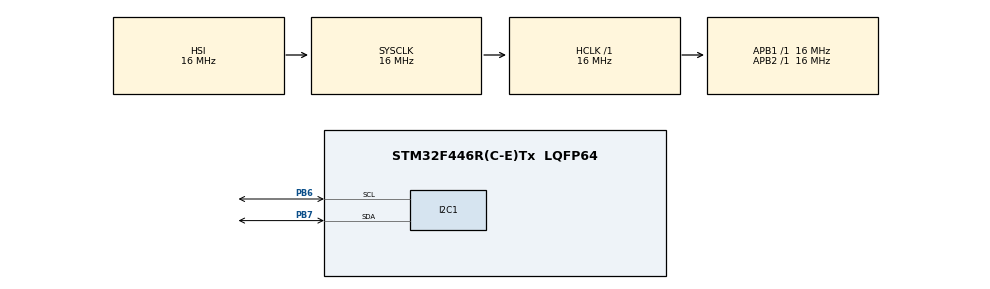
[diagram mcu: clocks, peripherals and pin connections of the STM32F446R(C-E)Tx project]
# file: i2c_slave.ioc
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I2C1.I2C_Mode=I2C_Fast
Mcu.Family=STM32F4
Mcu.Name=STM32F446R(C-E)Tx
Mcu.Package=LQFP64
NVIC.PriorityGroup=NVIC_PRIORITYGROUP_4
PB6.Mode=I2C
PB6.Signal=I2C1_SCL
PB7.Mode=I2C
PB7.Signal=I2C1_SDA
ProjectManager.HeapSize=0x200
ProjectManager.StackSize=0x400
ProjectManager.TargetToolchain=STM32CubeIDE
RCC.AHBFreq_Value=16000000
RCC.APB1Freq_Value=16000000
RCC.APB1TimFreq_Value=16000000
RCC.APB2Freq_Value=16000000
RCC.APB2TimFreq_Value=16000000
RCC.CortexFreq_Value=16000000
RCC.HCLKFreq_Value=16000000
RCC.SYSCLKFreq_VALUE=16000000
RCC.USBFreq_Value=96000000
RCC.VCOOutputFreq_Value=192000000
board=custom

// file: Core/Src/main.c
/* USER CODE BEGIN Header */
/**
  ******************************************************************************
  * @file           : main.c
  * @brief          : Main program body
  ******************************************************************************
  * @attention
  *
  * Copyright (c) 2026 STMicroelectronics.
  * All rights reserved.
  *
  * This software is licensed under terms that can be found in the LICENSE file
  * in the root directory of this software component.
  * If no LICENSE file comes with this software, it is provided AS-IS.
  *
  ******************************************************************************
  */
/* USER CODE END Header */
#include "main.h"

/* USER CODE BEGIN PD */
#define I2C_SLAVE_ADDR  0x50U   // 마스터(C2000)의 I2C_SLAVE_ADDR 과 동일 (7비트)
#define I2C_TX_BYTES    2U      // 마스터의 I2C_READ_BYTES 와 동일

/* USER CODE END PD */

I2C_HandleTypeDef hi2c1;

/* USER CODE BEGIN PV */
uint8_t txData[I2C_TX_BYTES] = {0x12, 0x34};   // 마스터로 보낼 데이터
volatile uint32_t txCount = 0;                   // 송신 성공 횟수 (디버깅용)

/* USER CODE END PV */

void SystemClock_Config(void);
static void MX_GPIO_Init(void);
static void MX_I2C1_Init(void);

int main(void)
{

  /* MCU Configuration--------------------------------------------------------*/

  /* Reset of all peripherals, Initializes the Flash interface and the Systick. */
  HAL_Init();

  /* Configure the system clock */
  SystemClock_Config();

  /* Initialize all configured peripherals */
  MX_GPIO_Init();
  MX_I2C1_Init();

  /* Infinite loop */
  while (1)
  {

    /* USER CODE BEGIN 3 */
    // 마스터가 자기 주소(0x50)로 READ 요청할 때까지 대기 후 txData 송신
    if (HAL_I2C_Slave_Transmit(&hi2c1, txData, I2C_TX_BYTES, 1000) == HAL_OK)
    {
      txCount++;
      txData[1]++;          // 테스트용: 매번 값이 바뀌는지 마스터에서 확인
    }
    else
    {
      // 타임아웃/에러 시 I2C 재초기화 후 다시 대기
      HAL_I2C_DeInit(&hi2c1);
      HAL_I2C_Init(&hi2c1);
    }
  }
  /* USER CODE END 3 */
}

void SystemClock_Config(void)
{
  RCC_OscInitTypeDef RCC_OscInitStruct = {0};
  RCC_ClkInitTypeDef RCC_ClkInitStruct = {0};

  /** Configure the main internal regulator output voltage
  */
  __HAL_RCC_PWR_CLK_ENABLE();
  __HAL_PWR_VOLTAGESCALING_CONFIG(PWR_REGULATOR_VOLTAGE_SCALE3);

  /** Initializes the RCC Oscillators according to the specified parameters
  * in the RCC_OscInitTypeDef structure.
  */
  RCC_OscInitStruct.OscillatorType = RCC_OSCILLATORTYPE_HSI;
  RCC_OscInitStruct.HSIState = RCC_HSI_ON;
  RCC_OscInitStruct.HSICalibrationValue = RCC_HSICALIBRATION_DEFAULT;
  RCC_OscInitStruct.PLL.PLLState = RCC_PLL_NONE;
  if (HAL_RCC_OscConfig(&RCC_OscInitStruct) != HAL_OK)
  {
    Error_Handler();
  }

  /** Initializes the CPU, AHB and APB buses clocks
  */
  RCC_ClkInitStruct.ClockType = RCC_CLOCKTYPE_HCLK|RCC_CLOCKTYPE_SYSCLK
                              |RCC_CLOCKTYPE_PCLK1|RCC_CLOCKTYPE_PCLK2;
  RCC_ClkInitStruct.SYSCLKSource = RCC_SYSCLKSOURCE_HSI;
  RCC_ClkInitStruct.AHBCLKDivider = RCC_SYSCLK_DIV1;
  RCC_ClkInitStruct.APB1CLKDivider = RCC_HCLK_DIV1;
  RCC_ClkInitStruct.APB2CLKDivider = RCC_HCLK_DIV1;

  if (HAL_RCC_ClockConfig(&RCC_ClkInitStruct, FLASH_LATENCY_0) != HAL_OK)
  {
    Error_Handler();
  }
}

static void MX_I2C1_Init(void)
{

  hi2c1.Instance = I2C1;
  hi2c1.Init.ClockSpeed = 400000;
  hi2c1.Init.DutyCycle = I2C_DUTYCYCLE_2;
  hi2c1.Init.OwnAddress1 = (I2C_SLAVE_ADDR << 1);   // HAL은 7비트 주소를 1비트 시프트해서 넣어야 함
  hi2c1.Init.AddressingMode = I2C_ADDRESSINGMODE_7BIT;
  hi2c1.Init.DualAddressMode = I2C_DUALADDRESS_DISABLE;
  hi2c1.Init.OwnAddress2 = 0;
  hi2c1.Init.GeneralCallMode = I2C_GENERALCALL_DISABLE;
  hi2c1.Init.NoStretchMode = I2C_NOSTRETCH_DISABLE;
  if (HAL_I2C_Init(&hi2c1) != HAL_OK)
  {
    Error_Handler();
  }

}

static void MX_GPIO_Init(void)
{

  /* GPIO Ports Clock Enable */
  __HAL_RCC_GPIOB_CLK_ENABLE();

}

void Error_Handler(void)
{
  __disable_irq();
  while (1)
  {
  }
}
